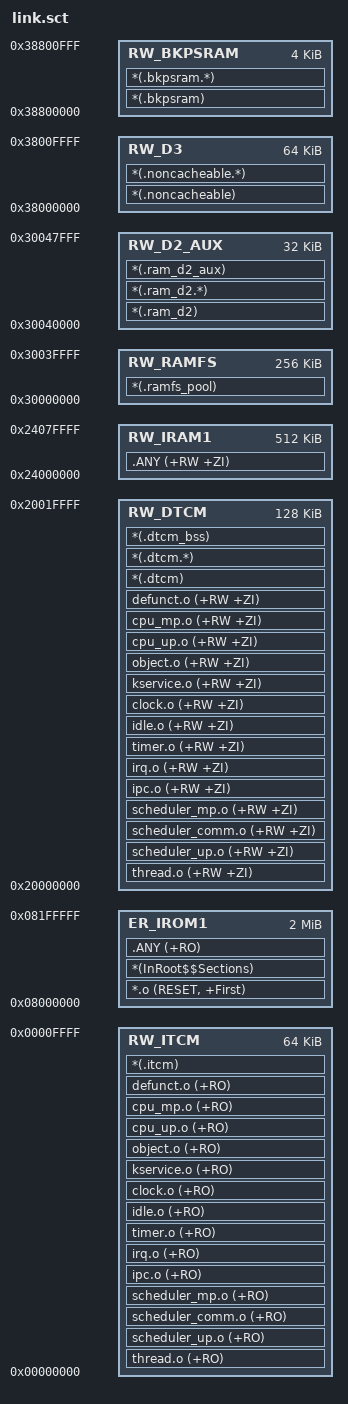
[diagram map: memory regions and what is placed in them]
; *************************************************************
; *** Scatter-Loading Description File for STM32H743IIT6    ***
; *************************************************************

LR_IROM1 0x08000000 0x00200000  {
  ER_IROM1 0x08000000 0x00200000  {
   *.o (RESET, +First)
   *(InRoot$$Sections)
   .ANY (+RO)
  }

  ; ITCM 64KB — RT-Thread 内核核心代码
  RW_ITCM 0x00000000 0x00010000  {
   thread.o (+RO)
   scheduler_up.o (+RO)
   scheduler_comm.o (+RO)
   scheduler_mp.o (+RO)
   ipc.o (+RO)
   irq.o (+RO)
   timer.o (+RO)
   idle.o (+RO)
   clock.o (+RO)
   kservice.o (+RO)
   object.o (+RO)
   cpu_up.o (+RO)
   cpu_mp.o (+RO)
   defunct.o (+RO)
   *(.itcm)
  }

  ; DTCM 128KB — 内核核心数据
  RW_DTCM 0x20000000 0x00020000  {
   thread.o (+RW +ZI)
   scheduler_up.o (+RW +ZI)
   scheduler_comm.o (+RW +ZI)
   scheduler_mp.o (+RW +ZI)
   ipc.o (+RW +ZI)
   irq.o (+RW +ZI)
   timer.o (+RW +ZI)
   idle.o (+RW +ZI)
   clock.o (+RW +ZI)
   kservice.o (+RW +ZI)
   object.o (+RW +ZI)
   cpu_up.o (+RW +ZI)
   cpu_mp.o (+RW +ZI)
   defunct.o (+RW +ZI)
   *(.dtcm)
   *(.dtcm.*)
   *(.dtcm_bss)
  }

  ; D1 AXI SRAM 512KB — 默认 RW/ZI/堆 (board.h HEAP_END)
  RW_IRAM1 0x24000000 0x00080000  {
   .ANY (+RW +ZI)
  }

  ; D2 SRAM1+2 256KB — dfs_ramfs
  RW_RAMFS 0x30000000 0x00040000  {
   *(.ramfs_pool)
  }

  ; D2 SRAM3 32KB — 其它 D2 用途
  RW_D2_AUX 0x30040000 0x00008000  {
   *(.ram_d2)
   *(.ram_d2.*)
   *(.ram_d2_aux)
  }

  ; D3 SRAM4 64KB — USB/DMA noncacheable
  RW_D3 0x38000000 0x00010000  {
   *(.noncacheable)
   *(.noncacheable.*)
  }

  ; Backup SRAM 4KB — 保留
  RW_BKPSRAM 0x38800000 0x00001000  {
   *(.bkpsram)
   *(.bkpsram.*)
  }
}
